# ESP32S31_RADIO register map
Vendor: Espressif; Series: ESP32-S31; File version: 3.52
Registers are 32-bit, read-write, no defined reset value unless marked. A register's access mark holds for its fields unless they carry their own. Offsets are from the block's base; [hi:lo] are bit positions; lines under a group give offsets from that group; {n}, {i} and the like mark numbered series; 'fields as' and 'values as' point back to an identical list.

## WIFI_MAC_TX_STATISTICS — Complete libpp.a[pp_debug.o]::dbg_lmac_hw_statis_dump reads these four consecutive words and prints them as txrts, txcts, track and trcts. It then reads the already canonical RX_TX_HANG/PANIC words at 0x20104e18/1c under its shorter txhung/panic labels. The blob applies no masks; the SVD therefore preserves each word without inventing subfields.
Base 0x20104E08
0x00 TX_RTS ro
  [31:0] VALUE
0x04 TX_CTS ro
  [31:0] VALUE
0x08 TRACK ro
  [31:0] VALUE
0x0C TRCTS ro — The abbreviated blob label is retained verbatim; its expansion is not yet proven.
  [31:0] VALUE

## WIFI_MAC_DIAGNOSTIC_STATISTICS — Complete libpp.a[pp_debug.o]::dbg_lmac_diag_statis_dump ties the blob's diag0 through diag12 and diagsel labels to these sparse MMIO words. The non-contiguous geometry and absence of diag11 are properties of the complete body. Higher-level meanings and internal bit widths remain unknown.
Base 0x201043B4
0x00 DIAG4 ro
  [31:0] VALUE
0x04 DIAG5 ro
  [31:0] VALUE
0x08 DIAG6 ro
  [31:0] VALUE
0x0C DIAG7 ro
  [31:0] VALUE
{0x10C+4i} DIAG{i} ro (i=8..10)
  [31:0] VALUE
0x138 DIAG12 ro
  [31:0] VALUE
{0xA9C+4i} DIAG{i} ro (i=0..2)
  [31:0] VALUE
0xAAC DIAG3 ro
  [31:0] VALUE
0xAB0 DIAG_SELECT ro
  [31:0] VALUE

## WIFI_MAC_RX_HANG_STATISTICS — Complete dbg_read_rx_count decodes two eight-bit hang counters and two full-width combined hang/panic counters. All four remained zero during the connected open HE matrix baseline.
Base 0x20104C64
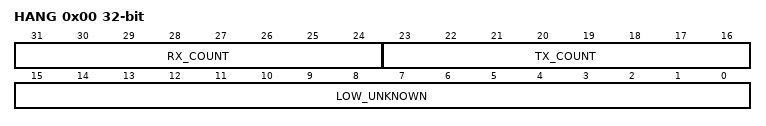
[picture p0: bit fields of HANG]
0x00 HANG ro
  [31:24] RX_COUNT, [23:16] TX_COUNT, [15:0] LOW_UNKNOWN
0x1B4 RX_TX_HANG ro — Complete dbg_read_rx_count names the combined counter RX_TX_HANG; complete pp_debug.o::dbg_lmac_hw_statis_dump independently reads the same full word under the shorter txhung label.
  [31:0] COUNT
0x1B8 RX_TX_PANIC ro — Complete dbg_read_rx_count names the combined counter RX_TX_PANIC; complete pp_debug.o::dbg_lmac_hw_statis_dump independently reads the same full word under the shorter panic label.
  [31:0] COUNT

## PHY_MEMORY — Shared PHY table-memory command, data and PBUS group-boundary aperture. The same command/data words have mode-dependent PBUS-memory, TX-CFR and gain-memory meanings; fields are named only where the complete bodies prove a common or mode-independent identity.
Base 0x20100800
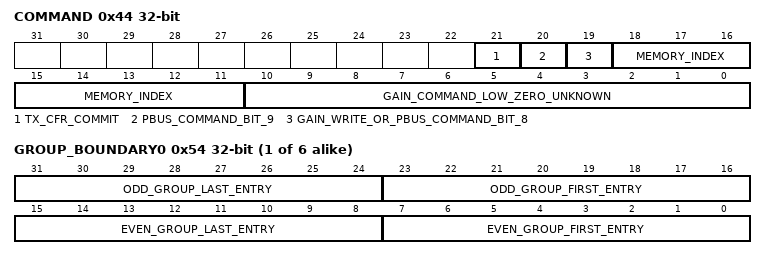
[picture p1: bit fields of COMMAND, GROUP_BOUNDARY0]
0x44 COMMAND — Shared memory command. Bits 20:11 carry the widest evidenced PBUS memory command; gain-memory and TX-CFR use narrower subsets.
  [21] TX_CFR_COMMIT — TX-CFR entry commit pulse.
  [20] PBUS_COMMAND_BIT_9 — PBUS command bit 9; CFR and gain-memory preserve it.
  [19] GAIN_WRITE_OR_PBUS_COMMAND_BIT_8 — Gain-memory write selector or PBUS command bit 8.
  [18:11] MEMORY_INDEX — Low eight bits of the PBUS command and complete CFR/gain memory index.
  [10:0] GAIN_COMMAND_LOW_ZERO_UNKNOWN — Gain-memory writes clear bits 10:0; their individual meanings are unknown.
0x48 DATA_0 wo — First shared table-memory data word; PBUS-memory and TX-CFR use only this word.
  [31:0] OPAQUE_DATA
0x4C DATA_1 wo — Second gain-memory data word.
  [31:0] OPAQUE_DATA
0x50 DATA_2 wo — Third gain-memory data word.
  [31:0] OPAQUE_DATA
{0x54+4i} GROUP_BOUNDARY{i} (i=0..5) — Packed first/last entry indices for one even/odd PBUS-memory group pair. Six words describe all twelve groups.
  [31:24] ODD_GROUP_LAST_ENTRY, [23:16] ODD_GROUP_FIRST_ENTRY, [15:8] EVEN_GROUP_LAST_ENTRY, [7:0] EVEN_GROUP_FIRST_ENTRY

## I2C_ANA_MST — Shared ESP32-S31 analog-register I2C master owned by the affine radio-PHY lifecycle.
Base 0x2010F800
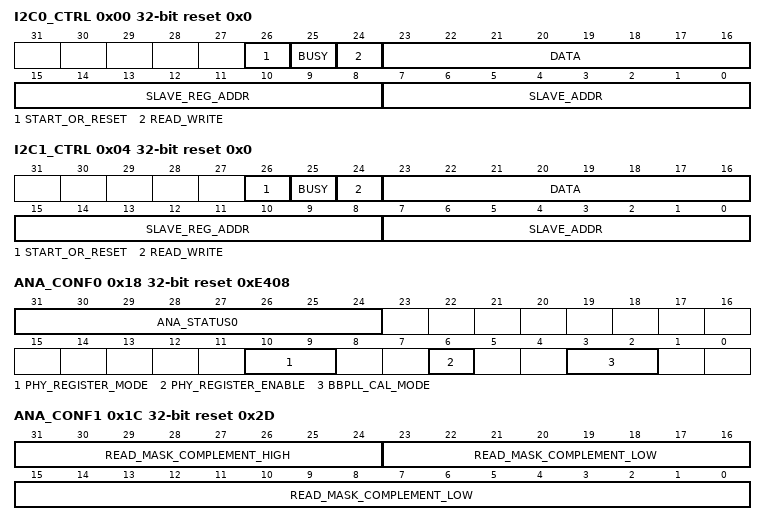
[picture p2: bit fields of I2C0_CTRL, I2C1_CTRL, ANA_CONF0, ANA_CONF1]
0x00 I2C0_CTRL reset 0x0 — Analog-register I2C host-0 command and completion word.
  [26] START_OR_RESET, [25] BUSY, [24] READ_WRITE, [23:16] DATA, [15:8] SLAVE_REG_ADDR, [7:0] SLAVE_ADDR
0x04 I2C1_CTRL reset 0x0 — Analog-register I2C host-1 command and completion word.
  fields as I2C0_CTRL
0x18 ANA_CONF0 reset 0xE408 — Shared analog-I2C master control used by PHY register mode and BBPLL calibration.
  [31:24] ANA_STATUS0
  [10:9] PHY_REGISTER_MODE
    2=REGISTER_MODE
  [6] PHY_REGISTER_ENABLE
  [3:2] BBPLL_CAL_MODE — Reviewed two-bit BBPLL calibration mode; complete ROM uses encodings one and two.
    1=DISABLED; 2=ENABLED
0x1C ANA_CONF1 reset 0x2D — Shared analog-I2C routing and read-mask word.
  [31:24] READ_MASK_COMPLEMENT_HIGH — High byte of the complete complemented PHY-I2C read-mask publication.
  [23:0] READ_MASK_COMPLEMENT_LOW — Low 24 bits of the complete complemented PHY-I2C read-mask publication.
0x20 ANA_CONF2 reset 0x4 — Shared analog-I2C host-selection word.
  [17:4] PHY_HOST_MAP — Complete host-selection field replaced by phy_get_i2c_hostid_new while unrelated bits are preserved.
    0x3FA0=REVIEWED_RADIO_MAP
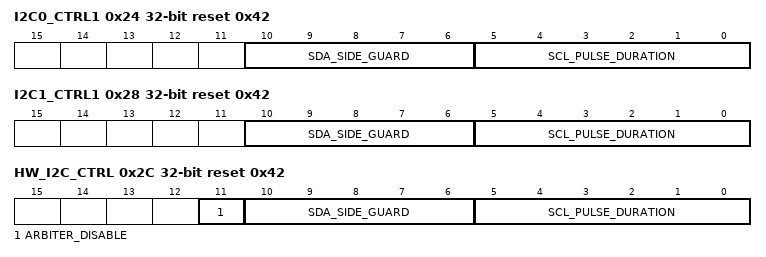
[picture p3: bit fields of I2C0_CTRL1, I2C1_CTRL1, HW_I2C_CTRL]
0x24 I2C0_CTRL1 reset 0x42 — Host-0 timing and clock-selection control.
  [10:6] SDA_SIDE_GUARD, [5:0] SCL_PULSE_DURATION
0x28 I2C1_CTRL1 reset 0x42 — Host-1 timing and clock-selection control.
  [10:6] SDA_SIDE_GUARD, [5:0] SCL_PULSE_DURATION
0x2C HW_I2C_CTRL reset 0x42 — Hardware-host timing and clock-selection control.
  [11] ARBITER_DISABLE, [10:6] SDA_SIDE_GUARD, [5:0] SCL_PULSE_DURATION
